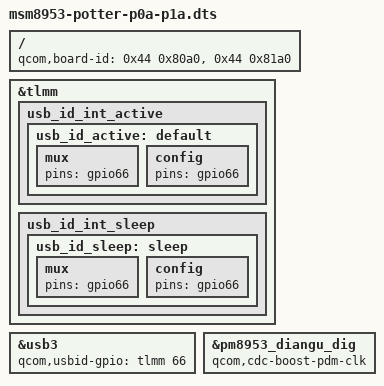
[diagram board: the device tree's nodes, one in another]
/* Copyright (c) 2015, Motorola Mobility Inc. All rights reserved.
 *
 * This program is free software; you can redistribute it and/or modify
 * it under the terms of the GNU General Public License version 2 and
 * only version 2 as published by the Free Software Foundation.
 *
 * This program is distributed in the hope that it will be useful,
 * but WITHOUT ANY WARRANTY; without even the implied warranty of
 * MERCHANTABILITY or FITNESS FOR A PARTICULAR PURPOSE.  See the
 * GNU General Public License for more details.
 */

/dts-v1/;


#include "msm8953-potter.dtsi"


/ {
	qcom,board-id = <0x44 0x80a0>,<0x44 0x81a0>;
};

&tlmm {
	usb_id_int_active {
		usb_id_active: default {
			mux {
				pins = "gpio66";
			};
			config {
				pins = "gpio66";
			};
		};
	};
	usb_id_int_sleep {
		usb_id_sleep: sleep {
			mux {
				pins = "gpio66";
			};
			config {
				pins = "gpio66";
			};
		};
	};
};
&usb3 {
	qcom,usbid-gpio = <&tlmm 66 0>;
};

&pm8953_diangu_dig {
	qcom,cdc-boost-pdm-clk;
};

